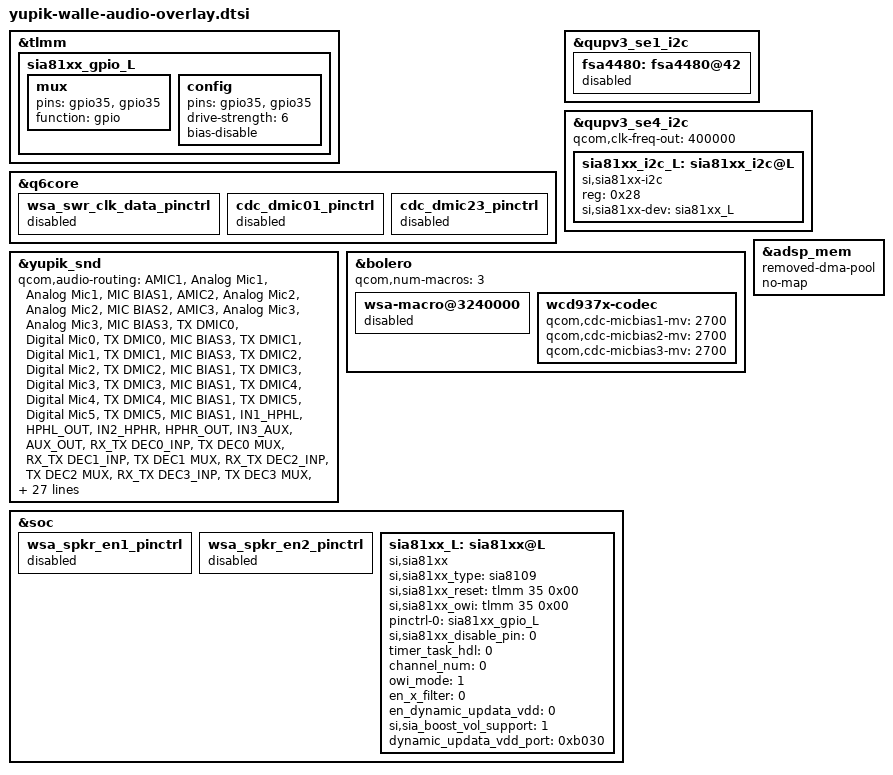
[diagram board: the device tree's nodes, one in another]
&tlmm {
	sia81xx_gpio_L: sia81xx_gpio_L {
		mux {
			pins = "gpio35", "gpio35";
			function = "gpio";
		};

		config {
			pins = "gpio35", "gpio35";
			drive-strength = <6>;
			bias-disable;
		};
	};
};

&q6core {
	wsa_swr_clk_data_pinctrl {
		status = "disabled";
	};
	cdc_dmic01_pinctrl{
		status = "disabled";
	};
	cdc_dmic23_pinctrl{
		status = "disabled";
	};
};

&yupik_snd {
	qcom,audio-routing =
		"AMIC1", "Analog Mic1",
		"Analog Mic1", "MIC BIAS1",
		"AMIC2", "Analog Mic2",
		"Analog Mic2", "MIC BIAS2",
		"AMIC3", "Analog Mic3",
		"Analog Mic3", "MIC BIAS3",
		//"AMIC4", "Analog Mic4",
		//"Analog Mic4", "MIC BIAS3",
		"TX DMIC0", "Digital Mic0",
		"TX DMIC0", "MIC BIAS3",
		"TX DMIC1", "Digital Mic1",
		"TX DMIC1", "MIC BIAS3",
		"TX DMIC2", "Digital Mic2",
		"TX DMIC2", "MIC BIAS1",
		"TX DMIC3", "Digital Mic3",
		"TX DMIC3", "MIC BIAS1",
		"TX DMIC4", "Digital Mic4",
		"TX DMIC4", "MIC BIAS1",
		"TX DMIC5", "Digital Mic5",
		"TX DMIC5", "MIC BIAS1",
		"IN1_HPHL", "HPHL_OUT",
		"IN2_HPHR", "HPHR_OUT",
		"IN3_AUX", "AUX_OUT",
		//"WSA SRC0_INP", "SRC0",
		//"WSA_TX DEC0_INP", "TX DEC0 MUX",
		//"WSA_TX DEC1_INP", "TX DEC1 MUX",
		"RX_TX DEC0_INP", "TX DEC0 MUX",
		"RX_TX DEC1_INP", "TX DEC1 MUX",
		"RX_TX DEC2_INP", "TX DEC2 MUX",
		"RX_TX DEC3_INP", "TX DEC3 MUX",
		//"SpkrLeft IN", "WSA_SPK1 OUT",
		//"SpkrRight IN", "WSA_SPK2 OUT",
		"TX SWR_INPUT", "WCD_TX_OUTPUT",
		"VA SWR_INPUT", "VA_SWR_CLK",
		"VA SWR_INPUT", "WCD_TX_OUTPUT",
		"VA_AIF1 CAP", "VA_SWR_CLK",
		"VA_AIF2 CAP", "VA_SWR_CLK",
		"VA_AIF3 CAP", "VA_SWR_CLK",
		"VA DMIC0", "Digital Mic0",
		"VA DMIC1", "Digital Mic1",
		"VA DMIC2", "Digital Mic2",
		"VA DMIC3", "Digital Mic3",
		"VA DMIC4", "Digital Mic4",
		"VA DMIC5", "Digital Mic5",
		"VA DMIC0", "VA MIC BIAS3",
		"VA DMIC1", "VA MIC BIAS3",
		"VA DMIC2", "VA MIC BIAS1",
		"VA DMIC3", "VA MIC BIAS1",
		"VA DMIC4", "VA MIC BIAS1",
		"VA DMIC5", "VA MIC BIAS1";
	qcom,msm-mbhc-hphl-swh = <1>;
	qcom,msm-mbhc-gnd-swh = <1>;
	qcom,msm-mbhc-moist-cfg = <1>, <3>, <0>;
	qcom,wsa-max-devs = <0>;
	/delete-property/ qcom,cdc-dmic01-gpios;
	/delete-property/ qcom,cdc-dmic23-gpios;
	qcom,msm-mbhc-hs-mic-max-threshold-mv = <2600>;
	qcom,msm-mbhc-hs-mic-min-threshold-mv = <75>;
	qcom,codec-max-aux-devs = <1>;
	qcom,codec-aux-devs = <&wcd937x_codec>;
	qcom,msm-mbhc-usbc-audio-supported = <0>;
	oplus,mbhc-headset-micbias-alwayon = <1>;
	oplus,speaker-pa = "sia81xx";
	si,sia81xx-max-num = <1>;
	si,sia81xx-aux-devs = <&sia81xx_L>;
	si,sia81xx-aux-devs-prefix = "SpkrMonoL";
	/* #ifdef OPLUS_FEATURE_4CH_AEC */
	qcom,afe-rxtx-lb = <1>;
	/* #endif OPLUS_FEATURE_4CH_AEC */
	/delete-property/ fsa4480-i2c-handle;
};

&qupv3_se1_i2c {
	fsa4480: fsa4480@42 {
		status = "disabled";
	};
};

&qupv3_se4_i2c {
	status = "ok";
	qcom,clk-freq-out = <400000>;
	sia81xx_i2c_L: sia81xx_i2c@L {
		compatible = "si,sia81xx-i2c";
		reg = <0x28>;
		si,sia81xx-dev = <&sia81xx_L>;
	};
};

&bolero {
	qcom,num-macros = <3>;
	wsa-macro@3240000 {
		status = "disabled";
	};
	wcd937x-codec {
		qcom,cdc-micbias1-mv = <2700>;
		qcom,cdc-micbias2-mv = <2700>;
		qcom,cdc-micbias3-mv = <2700>;
	};
};

&soc {
	wsa_spkr_en1_pinctrl {
		status = "disabled";
	};
	wsa_spkr_en2_pinctrl {
		status = "disabled";
	};
	sia81xx_L: sia81xx@L {
		compatible = "si,sia81xx";
		si,sia81xx_type = "sia8109";
		si,sia81xx_reset = <&tlmm 35 0x00>;
		si,sia81xx_owi = <&tlmm 35 0x00>;
		pinctrl-names = "sia81xx_gpio";
		pinctrl-0 = <&sia81xx_gpio_L>;

		si,sia81xx_disable_pin = <0>;

		/* the same value share a same task
		 * valid value range : 0 ~ 7 */
		timer_task_hdl = <0>;

		channel_num = <0>;
		owi_mode = <1>;
		en_x_filter = <0>;
		en_dynamic_updata_vdd = <0>;
		si,sia_boost_vol_support = <1>;
		dynamic_updata_vdd_port = <0xb030>;
	};
};

&adsp_mem {
	compatible = "removed-dma-pool";
	no-map;
	/delete-property/ reusable;
};
